# STM8L151K6 register map
Vendor: STMicroelectronics; Series: STM8L/STM8AL, medium density; File version: 1.0
CPU: other r1p0, big endian, no MPU, no FPU, 4 interrupt priority bits
Registers are 8-bit, read-write, reset 0x0 unless marked. A register's access mark holds for its fields unless they carry their own. Offsets are from the block's base; [hi:lo] are bit positions; {n}, {i} and the like mark numbered series.

## RST
Base 0x000050B0
0x00 CR — Reset control register
  [7:0] RSTPIN_KEY
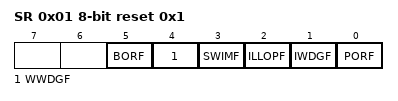
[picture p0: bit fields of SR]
0x01 SR reset 0x1 — Reset status register
  [5] BORF, [4] WWDGF, [3] SWIMF, [2] ILLOPF, [1] IWDGF, [0] PORF

## RTC
Base 0x00005140
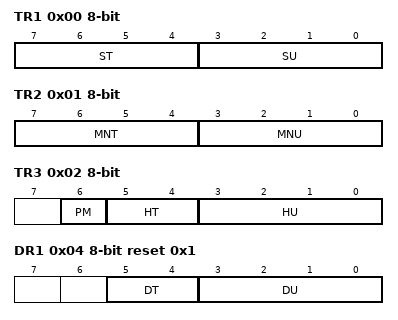
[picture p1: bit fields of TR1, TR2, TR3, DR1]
0x00 TR1 — Time register 1
  [7:4] ST, [3:0] SU
0x01 TR2 — Time register 2
  [7:4] MNT, [3:0] MNU
0x02 TR3 — Time register 3
  [6] PM, [5:4] HT, [3:0] HU
0x04 DR1 reset 0x1 — Date register 1
  [5:4] DT, [3:0] DU
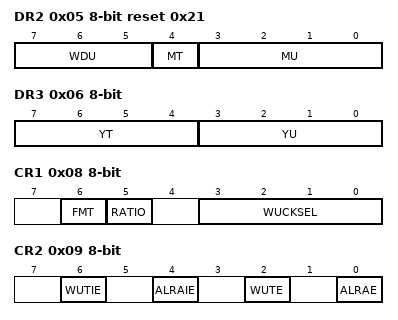
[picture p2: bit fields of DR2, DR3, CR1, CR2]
0x05 DR2 reset 0x21 — Date register 2
  [7:5] WDU, [4] MT, [3:0] MU
0x06 DR3 — Date register 3
  [7:4] YT, [3:0] YU
0x08 CR1 — Control register 1
  [6] FMT, [5] RATIO, [3:0] WUCKSEL
0x09 CR2 — Control register 2
  [6] WUTIE, [4] ALRAIE, [2] WUTE, [0] ALRAE
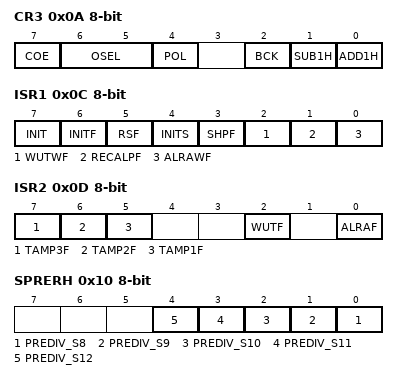
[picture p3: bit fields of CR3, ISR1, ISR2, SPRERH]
0x0A CR3 — Control register 3
  [7] COE, [6:5] OSEL, [4] POL, [2] BCK, [1] SUB1H, [0] ADD1H
0x0C ISR1 — Initialization and status register 1
  [7] INIT, [6] INITF, [5] RSF, [4] INITS, [3] SHPF, [2] WUTWF, [1] RECALPF, [0] ALRAWF
0x0D ISR2 — Initialization and Status register 2
  [7] TAMP3F, [6] TAMP2F, [5] TAMP1F, [2] WUTF, [0] ALRAF
0x10 SPRERH — Synchronous prescaler register high
  [n-8] PREDIV_S{n} (n=8..12)
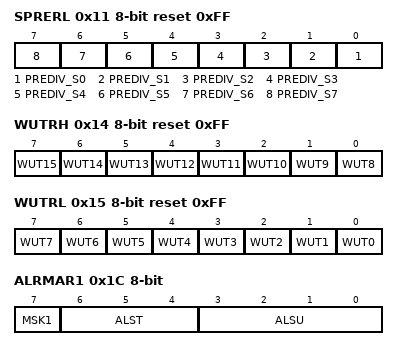
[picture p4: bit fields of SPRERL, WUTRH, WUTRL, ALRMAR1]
0x11 SPRERL reset 0xFF — Synchronous prescaler register low
  [n] PREDIV_S{n} (n=0..7)
0x12 APRER reset 0x7F — Asynchronous prescaler register
  [6:0] PREDIV_A
0x14 WUTRH reset 0xFF — Wakeup timer register high
  [n-8] WUT{n} (n=8..15)
0x15 WUTRL reset 0xFF — Wakeup timer register low
  [n] WUT{n} (n=0..7)
0x19 WPR — Write protection register
  [7:0] KEY
0x1C ALRMAR1 — Alarm A register 1
  [7] MSK1, [6:4] ALST, [3:0] ALSU
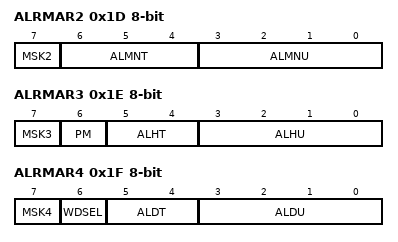
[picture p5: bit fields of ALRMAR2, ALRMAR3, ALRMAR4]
0x1D ALRMAR2 — Alarm A register 2
  [7] MSK2, [6:4] ALMNT, [3:0] ALMNU
0x1E ALRMAR3 — Alarm A register 3
  [7] MSK3, [6] PM, [5:4] ALHT, [3:0] ALHU
0x1F ALRMAR4 — Alarm A register 4
  [7] MSK4, [6] WDSEL, [5:4] ALDT, [3:0] ALDU

## SPI1
Base 0x00005200
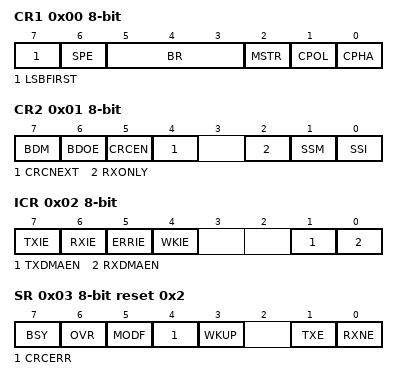
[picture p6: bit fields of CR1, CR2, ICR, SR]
0x00 CR1 — SPI1 control register 1
  [7] LSBFIRST, [6] SPE, [5:3] BR, [2] MSTR, [1] CPOL, [0] CPHA
0x01 CR2 — SPI1 control register 2
  [7] BDM, [6] BDOE, [5] CRCEN, [4] CRCNEXT, [2] RXONLY, [1] SSM, [0] SSI
0x02 ICR — SPI1 interrupt control register
  [7] TXIE, [6] RXIE, [5] ERRIE, [4] WKIE, [1] TXDMAEN, [0] RXDMAEN
0x03 SR reset 0x2 — SPI1 status register
  [7] BSY, [6] OVR, [5] MODF, [4] CRCERR, [3] WKUP, [1] TXE, [0] RXNE
0x04 DR — SPI1 data register
0x05 CRCPR reset 0x7 — SPI1 CRC polynomial register
  [7:0] CRCPOLY
0x06 RXCRCR — SPI1 Rx CRC register
  [7:0] RXCRC
0x07 TXCRCR — SPI1 Tx CRC register
  [6:0] TXCRC

## SWIM
Base 0x00007F80
0x00 CSR — SWIM control status register

## TIM1
Base 0x000052B0
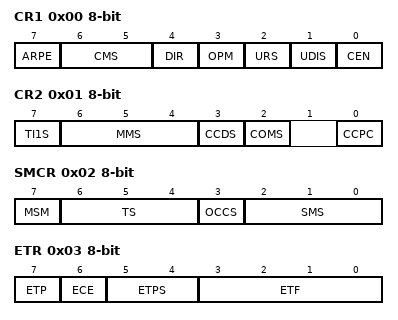
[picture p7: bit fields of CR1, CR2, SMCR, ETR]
0x00 CR1 — TIM1 control register 1
  [7] ARPE, [6:5] CMS, [4] DIR, [3] OPM, [2] URS, [1] UDIS, [0] CEN
0x01 CR2 — TIM1 control register 2
  [7] TI1S, [6:4] MMS, [3] CCDS, [2] COMS, [0] CCPC
0x02 SMCR — TIM1 Slave mode control register
  [7] MSM, [6:4] TS, [3] OCCS, [2:0] SMS
0x03 ETR — TIM1 external trigger register
  [7] ETP, [6] ECE, [5:4] ETPS, [3:0] ETF
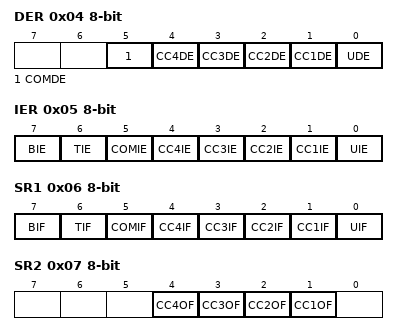
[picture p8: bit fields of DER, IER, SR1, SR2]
0x04 DER — TIM1 DMA1 request enable register
  [5] COMDE, [n] CC{n}DE (n=1..4), [0] UDE
0x05 IER — TIM1 Interrupt enable register
  [7] BIE, [6] TIE, [5] COMIE, [n] CC{n}IE (n=1..4), [0] UIE
0x06 SR1 — TIM1 status register 1
  [7] BIF, [6] TIF, [5] COMIF, [n] CC{n}IF (n=1..4), [0] UIF
0x07 SR2 — TIM1 status register 2
  [n] CC{n}OF (n=1..4)
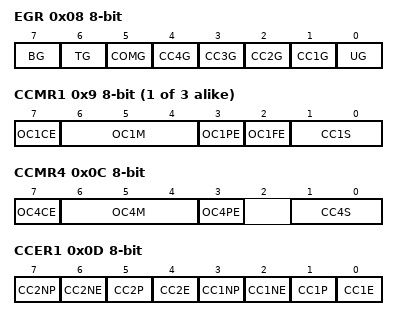
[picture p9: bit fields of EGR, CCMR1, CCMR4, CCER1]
0x08 EGR — TIM1 event generation register
  [7] BG, [6] TG, [5] COMG, [n] CC{n}G (n=1..4), [0] UG
{0x8+i} CCMR{i} (i=1..3) — TIM1 Capture/Compare mode register {i}
  [7] OC{i}CE, [6:4] OC{i}M, [3] OC{i}PE, [2] OC{i}FE, [1:0] CC{i}S
0x0C CCMR4 — TIM1 Capture/Compare mode register 4
  [7] OC4CE, [6:4] OC4M, [3] OC4PE, [1:0] CC4S
0x0D CCER1 — TIM1 Capture/Compare enable register 1
  [7] CC2NP, [6] CC2NE, [5] CC2P, [4] CC2E, [3] CC1NP, [2] CC1NE, [1] CC1P, [0] CC1E
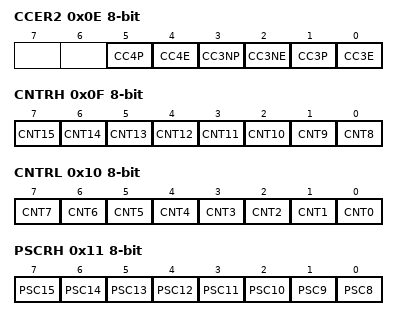
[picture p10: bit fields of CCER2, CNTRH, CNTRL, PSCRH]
0x0E CCER2 — TIM1 Capture/Compare enable register 2
  [5] CC4P, [4] CC4E, [3] CC3NP, [2] CC3NE, [1] CC3P, [0] CC3E
0x0F CNTRH — TIM1 counter high
  [n-8] CNT{n} (n=8..15)
0x10 CNTRL — TIM1 counter low
  [n] CNT{n} (n=0..7)
0x11 PSCRH — TIM1 prescaler register high
  [n-8] PSC{n} (n=8..15)
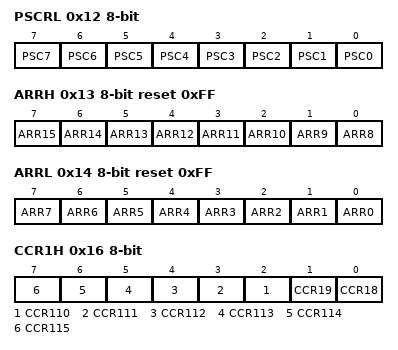
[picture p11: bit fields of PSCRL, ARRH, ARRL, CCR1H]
0x12 PSCRL — TIM1 prescaler register low
  [n] PSC{n} (n=0..7)
0x13 ARRH reset 0xFF — TIM1 Auto-reload register high
  [n-8] ARR{n} (n=8..15)
0x14 ARRL reset 0xFF — TIM1 Auto-reload register low
  [n] ARR{n} (n=0..7)
0x15 RCR — TIM1 Repetition counter register
  [7:0] REP
0x16 CCR1H — TIM1 Capture/Compare register 1 high
  [n-108] CCR{n} (n=110..115), [1] CCR19, [0] CCR18
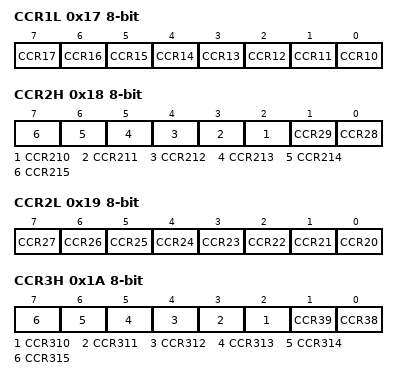
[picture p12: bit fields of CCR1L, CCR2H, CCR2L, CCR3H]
0x17 CCR1L — TIM1 Capture/Compare register 1 low
  [n-10] CCR{n} (n=10..17)
0x18 CCR2H — TIM1 Capture/Compare register 2 high
  [n-208] CCR{n} (n=210..215), [1] CCR29, [0] CCR28
0x19 CCR2L — TIM1 Capture/Compare register 2 low
  [n-20] CCR{n} (n=20..27)
0x1A CCR3H — TIM1 Capture/Compare register 3 high
  [n-308] CCR{n} (n=310..315), [1] CCR39, [0] CCR38
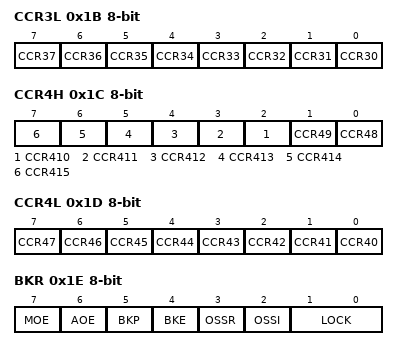
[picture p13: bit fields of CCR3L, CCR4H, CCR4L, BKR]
0x1B CCR3L — TIM1 Capture/Compare register 3 low
  [n-30] CCR{n} (n=30..37)
0x1C CCR4H — TIM1 Capture/Compare register 4 high
  [n-408] CCR{n} (n=410..415), [1] CCR49, [0] CCR48
0x1D CCR4L — TIM1 Capture/Compare register 4 low
  [n-40] CCR{n} (n=40..47)
0x1E BKR — TIM1 break register
  [7] MOE, [6] AOE, [5] BKP, [4] BKE, [3] OSSR, [2] OSSI, [1:0] LOCK
0x1F DTR — TIM1 dead-time register
  [7:0] DTG
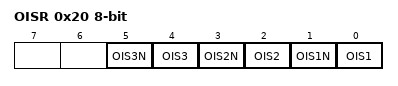
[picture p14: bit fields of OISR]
0x20 OISR — TIM1 output idle state register
  [5] OIS3N, [4] OIS3, [3] OIS2N, [2] OIS2, [1] OIS1N, [0] OIS1
0x21 DCR1 — DMA1 control register 1
  [4:0] DBA
0x22 DCR2 — TIM1 DMA1 control register 2
  [4:0] DBL
0x23 DMA1R — TIM1 DMA1 address for burst mode
  [7:0] DMAB
